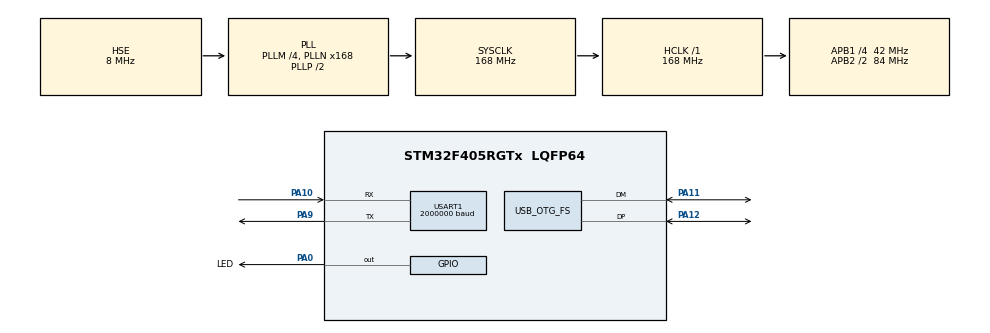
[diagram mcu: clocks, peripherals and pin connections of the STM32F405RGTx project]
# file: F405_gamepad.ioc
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Dma.Request0=USART1_RX
Dma.Request1=USART1_TX
Dma.USART1_RX.0.Direction=DMA_PERIPH_TO_MEMORY
Dma.USART1_RX.0.FIFOMode=DMA_FIFOMODE_DISABLE
Dma.USART1_RX.0.Instance=DMA2_Stream2
Dma.USART1_RX.0.MemDataAlignment=DMA_MDATAALIGN_BYTE
Dma.USART1_RX.0.MemInc=DMA_MINC_ENABLE
Dma.USART1_RX.0.Mode=DMA_NORMAL
Dma.USART1_RX.0.PeriphDataAlignment=DMA_PDATAALIGN_BYTE
Dma.USART1_RX.0.PeriphInc=DMA_PINC_DISABLE
Dma.USART1_RX.0.Priority=DMA_PRIORITY_LOW
Dma.USART1_TX.1.Direction=DMA_MEMORY_TO_PERIPH
Dma.USART1_TX.1.FIFOMode=DMA_FIFOMODE_DISABLE
Dma.USART1_TX.1.Instance=DMA2_Stream7
Dma.USART1_TX.1.MemDataAlignment=DMA_MDATAALIGN_BYTE
Dma.USART1_TX.1.MemInc=DMA_MINC_ENABLE
Dma.USART1_TX.1.Mode=DMA_NORMAL
Dma.USART1_TX.1.PeriphDataAlignment=DMA_PDATAALIGN_BYTE
Dma.USART1_TX.1.PeriphInc=DMA_PINC_DISABLE
Dma.USART1_TX.1.Priority=DMA_PRIORITY_LOW
FREERTOS.Tasks01=defaultTask,24,128,StartDefaultTask,Default,NULL,Dynamic,NULL,NULL;sys,24,256,app_sys,As weak,NULL,Dynamic,NULL,NULL;gamepad,8,256,app_gamepad,As weak,NULL,Dynamic,NULL,NULL
FREERTOS.configENABLE_FPU=1
Mcu.Family=STM32F4
Mcu.Name=STM32F405RGTx
Mcu.Package=LQFP64
NVIC.DMA2_Stream2_IRQn=true\:5\:0\:false\:false\:true\:true\:false\:true\:true
NVIC.DMA2_Stream7_IRQn=true\:5\:0\:false\:false\:true\:true\:false\:true\:true
NVIC.OTG_FS_IRQn=true\:5\:0\:false\:false\:true\:true\:false\:true\:true
NVIC.PriorityGroup=NVIC_PRIORITYGROUP_4
NVIC.TIM8_TRG_COM_TIM14_IRQn=true\:15\:0\:false\:false\:true\:false\:false\:true\:true
NVIC.TimeBase=TIM8_TRG_COM_TIM14_IRQn
NVIC.TimeBaseIP=TIM14
NVIC.USART1_IRQn=true\:5\:0\:false\:false\:true\:true\:true\:true\:true
PA0-WKUP.GPIO_Label=LED
PA0-WKUP.Signal=GPIO_Output
PA10.Mode=Asynchronous
PA10.Signal=USART1_RX
PA11.Mode=Host_Only
PA11.Signal=USB_OTG_FS_DM
PA12.Mode=Host_Only
PA12.Signal=USB_OTG_FS_DP
PA13.Mode=Serial_Wire
PA13.Signal=SYS_JTMS-SWDIO
PA14.Mode=Serial_Wire
PA14.Signal=SYS_JTCK-SWCLK
PA9.Mode=Asynchronous
PA9.Signal=USART1_TX
PC14-OSC32_IN.Mode=LSE-External-Oscillator
PC14-OSC32_IN.Signal=RCC_OSC32_IN
PC15-OSC32_OUT.Mode=LSE-External-Oscillator
PC15-OSC32_OUT.Signal=RCC_OSC32_OUT
PH0-OSC_IN.Mode=HSE-External-Oscillator
PH0-OSC_IN.Signal=RCC_OSC_IN
PH1-OSC_OUT.Mode=HSE-External-Oscillator
PH1-OSC_OUT.Signal=RCC_OSC_OUT
ProjectManager.HeapSize=0x200
ProjectManager.StackSize=0x400
ProjectManager.TargetToolchain=CMake
RCC.48MHZClocksFreq_Value=48000000
RCC.AHBFreq_Value=168000000
RCC.APB1CLKDivider=RCC_HCLK_DIV4
RCC.APB1Freq_Value=42000000
RCC.APB1TimFreq_Value=84000000
RCC.APB2CLKDivider=RCC_HCLK_DIV2
RCC.APB2Freq_Value=84000000
RCC.APB2TimFreq_Value=168000000
RCC.CortexFreq_Value=168000000
RCC.HCLKFreq_Value=168000000
RCC.HSE_VALUE=8000000
RCC.HSI_VALUE=16000000
RCC.PLLM=4
RCC.PLLN=168
RCC.PLLQ=7
RCC.SYSCLKFreq_VALUE=168000000
RCC.SYSCLKSource=RCC_SYSCLKSOURCE_PLLCLK
RCC.VCOOutputFreq_Value=336000000
USART1.BaudRate=2000000
USART1.VirtualMode=VM_ASYNC
USB_HOST.SW_VBUS_DRIVE_HID_FS=true
USB_HOST.USBH_HandleTypeDef-HID_FS=hUsbHostFS
USB_HOST.USBH_PROCESS_STACK_SIZE-HID_FS=512
USB_HOST.USBH_USE_OS-HID_FS=0
USB_HOST.VirtualModeFS=Hid
USB_OTG_FS.VirtualMode=Host_Only
USB_OTG_FS.phy_itface=HCD_PHY_EMBEDDED
VP_FREERTOS_VS_CMSIS_V2.Mode=CMSIS_V2
VP_SYS_VS_tim14.Mode=TIM14
VP_TIM7_VS_ClockSourceINT.Mode=Enable_Timer
VP_USB_HOST_VS_USB_HOST_HID_FS.Mode=HID_FS
board=custom

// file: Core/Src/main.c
/* USER CODE BEGIN Header */
/**
  ******************************************************************************
  * @file           : main.c
  * @brief          : Main program body
  ******************************************************************************
  * @attention
  *
  * Copyright (c) 2026 STMicroelectronics.
  * All rights reserved.
  *
  * This software is licensed under terms that can be found in the LICENSE file
  * in the root directory of this software component.
  * If no LICENSE file comes with this software, it is provided AS-IS.
  *
  ******************************************************************************
  */
/* USER CODE END Header */
#include "main.h"
#include "cmsis_os.h"
#include "dma.h"
#include "tim.h"
#include "usart.h"
#include "usb_host.h"
#include "gpio.h"

/* USER CODE BEGIN Includes */
#include "app_sys.h"
/* USER CODE END Includes */

void SystemClock_Config(void);
void MX_FREERTOS_Init(void);

int main(void)
{

  /* MCU Configuration--------------------------------------------------------*/

  /* Reset of all peripherals, Initializes the Flash interface and the Systick. */
  HAL_Init();

  /* USER CODE BEGIN Init */
  HAL_RCC_DeInit();
  /* USER CODE END Init */

  /* Configure the system clock */
  SystemClock_Config();

  /* Initialize all configured peripherals */
  MX_GPIO_Init();
  MX_DMA_Init();
  MX_USART1_UART_Init();
  MX_TIM7_Init();
  /* USER CODE BEGIN 2 */
  sys_main_init();
  /* USER CODE END 2 */

  /* Init scheduler */
  osKernelInitialize();  /* Call init function for freertos objects (in cmsis_os2.c) */
  MX_FREERTOS_Init();

  /* Start scheduler */
  osKernelStart();

  /* We should never get here as control is now taken by the scheduler */

  /* Infinite loop */
  while (1)
  {

  }
}

void SystemClock_Config(void)
{
  RCC_OscInitTypeDef RCC_OscInitStruct = {0};
  RCC_ClkInitTypeDef RCC_ClkInitStruct = {0};

  /** Configure the main internal regulator output voltage
  */
  __HAL_RCC_PWR_CLK_ENABLE();
  __HAL_PWR_VOLTAGESCALING_CONFIG(PWR_REGULATOR_VOLTAGE_SCALE1);

  /** Initializes the RCC Oscillators according to the specified parameters
  * in the RCC_OscInitTypeDef structure.
  */
  RCC_OscInitStruct.OscillatorType = RCC_OSCILLATORTYPE_HSE;
  RCC_OscInitStruct.HSEState = RCC_HSE_ON;
  RCC_OscInitStruct.PLL.PLLState = RCC_PLL_ON;
  RCC_OscInitStruct.PLL.PLLSource = RCC_PLLSOURCE_HSE;
  RCC_OscInitStruct.PLL.PLLM = 4;
  RCC_OscInitStruct.PLL.PLLN = 168;
  RCC_OscInitStruct.PLL.PLLP = RCC_PLLP_DIV2;
  RCC_OscInitStruct.PLL.PLLQ = 7;
  if (HAL_RCC_OscConfig(&RCC_OscInitStruct) != HAL_OK)
  {
    Error_Handler();
  }

  /** Initializes the CPU, AHB and APB buses clocks
  */
  RCC_ClkInitStruct.ClockType = RCC_CLOCKTYPE_HCLK|RCC_CLOCKTYPE_SYSCLK
                              |RCC_CLOCKTYPE_PCLK1|RCC_CLOCKTYPE_PCLK2;
  RCC_ClkInitStruct.SYSCLKSource = RCC_SYSCLKSOURCE_PLLCLK;
  RCC_ClkInitStruct.AHBCLKDivider = RCC_SYSCLK_DIV1;
  RCC_ClkInitStruct.APB1CLKDivider = RCC_HCLK_DIV4;
  RCC_ClkInitStruct.APB2CLKDivider = RCC_HCLK_DIV2;

  if (HAL_RCC_ClockConfig(&RCC_ClkInitStruct, FLASH_LATENCY_5) != HAL_OK)
  {
    Error_Handler();
  }
}

void HAL_TIM_PeriodElapsedCallback(TIM_HandleTypeDef *htim)
{
  if (htim->Instance == TIM14)
  {
    HAL_IncTick();
  }
}

void Error_Handler(void)
{
  __disable_irq();
  while (1)
  {
  }
}

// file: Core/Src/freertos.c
/* USER CODE BEGIN Header */
/**
  ******************************************************************************
  * File Name          : freertos.c
  * Description        : Code for freertos applications
  ******************************************************************************
  * @attention
  *
  * Copyright (c) 2026 STMicroelectronics.
  * All rights reserved.
  *
  * This software is licensed under terms that can be found in the LICENSE file
  * in the root directory of this software component.
  * If no LICENSE file comes with this software, it is provided AS-IS.
  *
  ******************************************************************************
  */
/* USER CODE END Header */

#include "FreeRTOS.h"
#include "task.h"
#include "main.h"
#include "cmsis_os.h"

/* Definitions for defaultTask */
osThreadId_t defaultTaskHandle;
const osThreadAttr_t defaultTask_attributes = {
  .name = "defaultTask",
  .stack_size = 128 * 4,
  .priority = (osPriority_t) osPriorityNormal,
};
/* Definitions for sys */
osThreadId_t sysHandle;
const osThreadAttr_t sys_attributes = {
  .name = "sys",
  .stack_size = 256 * 4,
  .priority = (osPriority_t) osPriorityNormal,
};
/* Definitions for gamepad */
osThreadId_t gamepadHandle;
const osThreadAttr_t gamepad_attributes = {
  .name = "gamepad",
  .stack_size = 256 * 4,
  .priority = (osPriority_t) osPriorityLow,
};

void StartDefaultTask(void *argument);
void app_sys(void *argument);
void app_gamepad(void *argument);

extern void MX_USB_HOST_Init(void);
void MX_FREERTOS_Init(void); /* (MISRA C 2004 rule 8.1) */

void MX_FREERTOS_Init(void) {

  /* Create the thread(s) */
  /* creation of defaultTask */
  defaultTaskHandle = osThreadNew(StartDefaultTask, NULL, &defaultTask_attributes);

  /* creation of sys */
  sysHandle = osThreadNew(app_sys, NULL, &sys_attributes);

  /* creation of gamepad */
  gamepadHandle = osThreadNew(app_gamepad, NULL, &gamepad_attributes);

}

void StartDefaultTask(void *argument)
{
  /* init code for USB_HOST */
  MX_USB_HOST_Init();
  for(;;)
  {
    osDelay(1);
  }
}

__weak void app_sys(void *argument)
{
  for(;;)
  {
    osDelay(1);
  }
}

__weak void app_gamepad(void *argument)
{
  for(;;)
  {
    osDelay(1);
  }
}
